AUTOSAR XML (schema 4-1-3)
standard types defined: uint16, uint32, uint16_DataConstr, uint32_DataConstr, uint8
package /ComponentTypes/DataTypeMappingSets
  data type mapping set DTMS_HvacDampr_DD
package /UAES/ASW/DataConstrs
  range DC_uint16: raw 0..65535
package /UAES/ASW/PortInterfaces
  client server interface IoHwAb_HbrModCtrl
    operation Hbr_SetMod: possible-error=IoHwAb_HbrModCtrl/E_NOT_OK
      arg id_u16: type=ImplementationDataTypes/uint16, direction=IN, server-argument-impl-policy=USE-ARGUMENT-TYPE
      arg mod_u8: type=ImplementationDataTypes/uint8, direction=IN, server-argument-impl-policy=USE-ARGUMENT-TYPE
    error E_NOT_OK: error-code=1
  client server interface IoHwAb_IoDiagHbr
    operation Hbr_Get: possible-error=IoHwAb_IoDiagHbr/E_NOT_OK
      arg id_u16: type=ImplementationDataTypes/uint16, direction=IN, server-argument-impl-policy=USE-ARGUMENT-TYPE
      arg val_u32: type=uint32, direction=OUT, server-argument-impl-policy=USE-ARGUMENT-TYPE
    error E_NOT_OK: error-code=1
  12 x sender receiver interface:
    gCFG_u8ReHVACBoxTyp: invalidation-policy{data-element=gCFG_u8ReHVACBoxTyp/Val, handle-invalid=DONT-INVALIDATE}
      data Val: sw-calibration-access=READ-ONLY, type=ImplementationDataTypes/uint8
    gPRM_u8AirConditionBoxSpecCfg: invalidation-policy{data-element=gPRM_u8AirConditionBoxSpecCfg/Val, handle-invalid=DONT-INVALIDATE}
      data Val: sw-calibration-access=READ-ONLY, type=ImplementationDataTypes/uint8
    gPRM_u8ReAirConditionBoxSpecCfg: invalidation-policy{data-element=gPRM_u8ReAirConditionBoxSpecCfg/Val, handle-invalid=DONT-INVALIDATE}
      data Val: sw-calibration-access=READ-ONLY, type=ImplementationDataTypes/uint8
    gPRM_u8VehicleTypeCfg: invalidation-policy{data-element=gPRM_u8VehicleTypeCfg/Val, handle-invalid=DONT-INVALIDATE}
      data Val: sw-calibration-access=READ-ONLY, range raw 0..255, type=ImplementationDataTypes/uint8
    HvacDampr_stDrvrMixMotDir: invalidation-policy{data-element=HvacDampr_stDrvrMixMotDir/Val, handle-invalid=DONT-INVALIDATE}
      data Val: sw-calibration-access=READ-ONLY, type=ImplementationDataTypes/uint8
    HvacDampr_stDrvrRcrltnMotDir: invalidation-policy{data-element=HvacDampr_stDrvrRcrltnMotDir/Val, handle-invalid=DONT-INVALIDATE}
      data Val: sw-calibration-access=READ-ONLY, type=ImplementationDataTypes/uint8
    HvacDampr_stModMotDir: invalidation-policy{data-element=HvacDampr_stModMotDir/Val, handle-invalid=DONT-INVALIDATE}
      data Val: sw-calibration-access=READ-ONLY, type=ImplementationDataTypes/uint8
    HvacDampr_stPassMixMotDir: invalidation-policy{data-element=HvacDampr_stPassMixMotDir/Val, handle-invalid=DONT-INVALIDATE}
      data Val: type=ImplementationDataTypes/uint8
    HvacDampr_stPassRcrltnMotDir: invalidation-policy{data-element=HvacDampr_stPassRcrltnMotDir/Val, handle-invalid=DONT-INVALIDATE}
      data Val: sw-calibration-access=READ-ONLY, type=ImplementationDataTypes/uint8
    HvacDampr_stRcrltnMotDir: invalidation-policy{data-element=HvacDampr_stRcrltnMotDir/Val, handle-invalid=DONT-INVALIDATE}
      data Val: sw-calibration-access=READ-ONLY, type=ImplementationDataTypes/uint8
    HvacDampr_stReMixMotDir: invalidation-policy{data-element=HvacDampr_stReMixMotDir/Val, handle-invalid=DONT-INVALIDATE}
      data Val: sw-calibration-access=READ-ONLY, type=ImplementationDataTypes/uint8
    HvacDampr_stReModMotDir: invalidation-policy{data-element=HvacDampr_stReModMotDir/Val, handle-invalid=DONT-INVALIDATE}
      data Val: sw-calibration-access=READ-ONLY, type=ImplementationDataTypes/uint8
package /UAES/ASW/SwComponentTypes
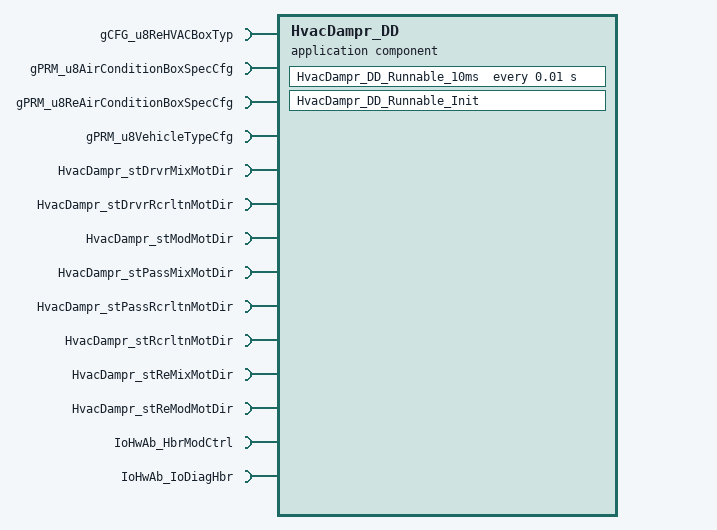
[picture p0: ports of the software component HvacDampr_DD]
  application sw component type HvacDampr_DD
    14 x require port:
      gCFG_u8ReHVACBoxTyp: nonqueued-receiver-com-spec{data-element=gCFG_u8ReHVACBoxTyp/Val, filter=data-filter-type=ALWAYS, init-value=0}, required-interface=gCFG_u8ReHVACBoxTyp
      gPRM_u8AirConditionBoxSpecCfg: nonqueued-receiver-com-spec{data-element=gPRM_u8AirConditionBoxSpecCfg/Val, filter=data-filter-type=ALWAYS, init-value=0}, required-interface=gPRM_u8AirConditionBoxSpecCfg
      gPRM_u8ReAirConditionBoxSpecCfg: nonqueued-receiver-com-spec{data-element=gPRM_u8ReAirConditionBoxSpecCfg/Val, filter=data-filter-type=ALWAYS, init-value=0}, required-interface=gPRM_u8ReAirConditionBoxSpecCfg
      gPRM_u8VehicleTypeCfg: nonqueued-receiver-com-spec{data-element=gPRM_u8VehicleTypeCfg/Val, filter=data-filter-type=ALWAYS, init-value=0}, required-interface=gPRM_u8VehicleTypeCfg
      HvacDampr_stDrvrMixMotDir: nonqueued-receiver-com-spec{data-element=HvacDampr_stDrvrMixMotDir/Val, filter=data-filter-type=ALWAYS, init-value=0}, required-interface=HvacDampr_stDrvrMixMotDir
      HvacDampr_stDrvrRcrltnMotDir: nonqueued-receiver-com-spec{data-element=HvacDampr_stDrvrRcrltnMotDir/Val, filter=data-filter-type=ALWAYS, init-value=0}, required-interface=HvacDampr_stDrvrRcrltnMotDir
      HvacDampr_stModMotDir: nonqueued-receiver-com-spec{data-element=HvacDampr_stModMotDir/Val, filter=data-filter-type=ALWAYS, init-value=0}, required-interface=HvacDampr_stModMotDir
      HvacDampr_stPassMixMotDir: nonqueued-receiver-com-spec{data-element=HvacDampr_stPassMixMotDir/Val, filter=data-filter-type=ALWAYS, init-value=0}, required-interface=HvacDampr_stPassMixMotDir
      HvacDampr_stPassRcrltnMotDir: nonqueued-receiver-com-spec{data-element=HvacDampr_stPassRcrltnMotDir/Val, filter=data-filter-type=ALWAYS, init-value=0}, required-interface=HvacDampr_stPassRcrltnMotDir
      HvacDampr_stRcrltnMotDir: nonqueued-receiver-com-spec{data-element=HvacDampr_stRcrltnMotDir/Val, filter=data-filter-type=ALWAYS, init-value=0}, required-interface=HvacDampr_stRcrltnMotDir
      HvacDampr_stReMixMotDir: nonqueued-receiver-com-spec{data-element=HvacDampr_stReMixMotDir/Val, filter=data-filter-type=ALWAYS, init-value=0}, required-interface=HvacDampr_stReMixMotDir
      HvacDampr_stReModMotDir: nonqueued-receiver-com-spec{data-element=HvacDampr_stReModMotDir/Val, filter=data-filter-type=ALWAYS, init-value=0}, required-interface=HvacDampr_stReModMotDir
      IoHwAb_HbrModCtrl: client-com-spec=Hbr_SetMod, required-interface=IoHwAb_HbrModCtrl
      IoHwAb_IoDiagHbr: client-com-spec=Hbr_Get, required-interface=IoHwAb_IoDiagHbr
    behavior HvacDampr_DD_InternalBehavior: data-type-mapping=DTMS_HvacDampr_DD
      timing event TMT_HvacDampr_DD_Runnable_100ms: start-on-event=HvacDampr_DD_Runnable_10ms, period=0.01
      init event HvacDampr_DD_InitEvent: start-on-event=HvacDampr_DD_Runnable_Init
      runnable HvacDampr_DD_Runnable_10ms
        data-receive-point-by-arguments:
          12 x access:
            REC_gCFG_u8ReHVACBoxTyp_Val: accessed-variable=gCFG_u8ReHVACBoxTyp.Val
            REC_gPRM_u8AirConditionBoxSpecCfg_Val: accessed-variable=gPRM_u8AirConditionBoxSpecCfg.Val
            REC_gPRM_u8ReAirConditionBoxSpecCfg_Val: accessed-variable=gPRM_u8ReAirConditionBoxSpecCfg.Val
            REC_gPRM_u8VehicleTypeCfg_Val: accessed-variable=gPRM_u8VehicleTypeCfg.Val
            REC_HvacDampr_stDrvrMixMotDir_Val: accessed-variable=HvacDampr_stDrvrMixMotDir.Val
            REC_HvacDampr_stDrvrRcrltnMotDir_Val: accessed-variable=HvacDampr_stDrvrRcrltnMotDir.Val
            REC_HvacDampr_stModMotDir_Val: accessed-variable=HvacDampr_stModMotDir.Val
            REC_HvacDampr_stPassMixMotDir_Val: accessed-variable=HvacDampr_stPassMixMotDir.Val
            REC_HvacDampr_stPassRcrltnMotDir_Val: accessed-variable=HvacDampr_stPassRcrltnMotDir.Val
            REC_HvacDampr_stRcrltnMotDir_Val: accessed-variable=HvacDampr_stRcrltnMotDir.Val
            REC_HvacDampr_stReMixMotDir_Val: accessed-variable=HvacDampr_stReMixMotDir.Val
            REC_HvacDampr_stReModMotDir_Val: accessed-variable=HvacDampr_stReModMotDir.Val
        sync call SC_IoHwAb_HbrModCtrl_Hbr_SetMod: operation=IoHwAb_HbrModCtrl.Hbr_SetMod, timeout=0
        sync call SC_IoHwAb_IoDiagHbr_Hbr_Get: operation=IoHwAb_IoDiagHbr.Hbr_Get, timeout=0
      runnable HvacDampr_DD_Runnable_Init
        data-receive-point-by-arguments:
          12 x access:
            REC_gCFG_u8ReHVACBoxTyp_Val: accessed-variable=gCFG_u8ReHVACBoxTyp.Val
            REC_gPRM_u8AirConditionBoxSpecCfg_Val: accessed-variable=gPRM_u8AirConditionBoxSpecCfg.Val
            REC_gPRM_u8ReAirConditionBoxSpecCfg_Val: accessed-variable=gPRM_u8ReAirConditionBoxSpecCfg.Val
            REC_gPRM_u8VehicleTypeCfg_Val: accessed-variable=gPRM_u8VehicleTypeCfg.Val
            REC_HvacDampr_stDrvrMixMotDir_Val: accessed-variable=HvacDampr_stDrvrMixMotDir.Val
            REC_HvacDampr_stDrvrRcrltnMotDir_Val: accessed-variable=HvacDampr_stDrvrRcrltnMotDir.Val
            REC_HvacDampr_stModMotDir_Val: accessed-variable=HvacDampr_stModMotDir.Val
            REC_HvacDampr_stPassMixMotDir_Val: accessed-variable=HvacDampr_stPassMixMotDir.Val
            REC_HvacDampr_stPassRcrltnMotDir_Val: accessed-variable=HvacDampr_stPassRcrltnMotDir.Val
            REC_HvacDampr_stRcrltnMotDir_Val: accessed-variable=HvacDampr_stRcrltnMotDir.Val
            REC_HvacDampr_stReMixMotDir_Val: accessed-variable=HvacDampr_stReMixMotDir.Val
            REC_HvacDampr_stReModMotDir_Val: accessed-variable=HvacDampr_stReModMotDir.Val
  swc implementation HvacDampr_DD_Implementation: behavior=HvacDampr_DD_InternalBehavior
    code-descriptors:
      code Default: artifact-descriptors=autosar-engineering-object={short-label=Default, category=SWSRC}
package /UAES/DataConstrs
  range DC_uint8: raw 0..255
